AUTOSAR XML (schema 4-2-1)
standard types defined: float32, float64, sint8, sint16, sint32, uint8, uint16, uint32, boolean, dtRef_VOID, Boolean, UInt8, Float32
package /FoundationPkg/FoundationArchitecturePkg
  client server interface iCalibrate
    operation calibrateStraightAhead
      arg action: type=tCalibrateCmd, direction=IN
    operation isStraightAheadCalibrated
      arg calibrated: type=Boolean, direction=OUT
    operation getCalibrateStatus
      arg status: type=tCalibrateState, direction=OUT
  client server interface iNvmJobFinished
    operation JobFinished
      arg ServiceId: type=NvM_ServiceIdType, direction=IN
      arg JobResult: type=NvM_RequestResultType, direction=IN
  constant specification iColumnNvm_AspCalibration_Init: value-spec={short-label=iColumnNvm_AspCalibration_Init, fields=[0 deg, 1, {short-label=tStraightAheadOffset_EQf_Init, fields=[1, 1, 1, 1]}]}
  sender receiver interface iColumnNvm
    data AspCalibration: sw-calibration-access=READ-ONLY, type=tStraightAheadOffset, init-value=constant-reference=iColumnNvm_AspCalibration_Init
  client server interface iRackSizing
    operation getMaxRackTravel
      arg maxRackTravel: type=Degrees, direction=OUT
  5 x constant specification:
    iColumnData_ColumnTorque_Init: value-spec={short-label=iColumnData_ColumnTorque_Init, fields=[0 Nm, 0 Nm/s, 0, {short-label=tInputTorque_EQf_Init, fields=[1, 1, 1, 1]}]}
    iColumnData_SteeringPositionLower_Init: value-spec={short-label=iColumnData_SteeringPositionLower_Init, fields=[0 deg, 0, {short-label=tColumnPosition_EQf_Init, fields=[1, 1, 1, 1]}]}
    iColumnData_ColumnVelocity_Init: value-spec={short-label=iColumnData_ColumnVelocity_Init, fields=[0 revs/S, 0 revs/S, 0]}
    iColumnData_SteeringPositionUpper_Init: value-spec={short-label=iColumnData_SteeringPositionUpper_Init, fields=[0 deg, 0, {short-label=tColumnPosition_EQf_Init, fields=[1, 1, 1, 1]}]}
    iColumnData_ColumnPositionLower_Init: value-spec={short-label=iColumnData_ColumnPositionLower_Init, fields=[0 deg, 0, {short-label=tColumnPosition_EQf_Init, fields=[1, 1, 1, 1]}]}
  sender receiver interface iColumnData
    5 x data, all with sw-calibration-access=READ-ONLY:
      ColumnTorque: type=tInputTorque, init-value=constant-reference=iColumnData_ColumnTorque_Init
      SteeringPositionLower: type=tColumnPosition, init-value=constant-reference=iColumnData_SteeringPositionLower_Init
      ColumnVelocity: type=tColumnVelocity, init-value=constant-reference=iColumnData_ColumnVelocity_Init
      SteeringPositionUpper: type=tColumnPosition, init-value=constant-reference=iColumnData_SteeringPositionUpper_Init
      ColumnPositionLower: type=tColumnPosition, init-value=constant-reference=iColumnData_ColumnPositionLower_Init
  client server interface iResetResPositions
    operation resetResLeRiPosition
      arg StraightAheadOffSet: type=tStraightAheadOffset, direction=IN
  constant specification iStraightAheadOffset_StraightAheadOffset_Init: value-spec={short-label=iStraightAheadOffset_StraightAheadOffset_Init, fields=[0 deg, 0, {short-label=tStraightAheadOffset_EQf_Init, fields=[1, 1, 1, 1]}]}
  sender receiver interface iStraightAheadOffset
    data StraightAheadOffset: sw-calibration-access=READ-ONLY, type=tStraightAheadOffset, init-value=constant-reference=iStraightAheadOffset_StraightAheadOffset_Init
package /FoundationPkg/FoundationArchitecturePkg/FoundationTypes
  impl type tCalibrateCmd: category=VALUE, base-type=sint32, compu {0=CAL_NO_COMMAND, 1=CAL_CALIBRATE, 2=CAL_ERASE}
  compu method tCalibrateState_Compu: 0=CAL_STATE_NOT_REQUESTED, 1=CAL_STATE_IN_PROGRESS, 2=CAL_STATE_COMPLETE, 3=CAL_STATE_FAILED_ANGLE_INVALID, 4=CAL_STATE_FAILED_IMPROPER_COL_TRQ, 5=CAL_STATE_FAILED_IMPROPER_COL_VEL, 6=CAL_STATE_FAILED_NVM_WRITE
  impl type tCalibrateState: category=VALUE, base-type=sint32, compu-method=tCalibrateState_Compu
  impl type NvM_ServiceIdType: implementation-data-type=UInt8
  unit Degrees_Unit: display-name=deg
  impl type Degrees: implementation-data-type=Float32
  compu method tQualityFactor_Compu: 0=QF_UNINITIALIZED, 0=QF_UNINITIALISED, 1=QF_UNAVAILABLE, 2=QF_DEGRADED, 3=QF_FULL
  impl type tQualityFactor: category=VALUE, base-type=sint32, compu-method=tQualityFactor_Compu
  impl type tRedundancyLevel: implementation-data-type=UInt8
  impl type tExtendedQf: category=STRUCTURE
    4 x element, all with category=TYPE_REFERENCE:
      IntegrityDegraded: implementation-data-type=Boolean
      ResolutionDegraded: implementation-data-type=Boolean
      Defaulted: implementation-data-type=Boolean
      RedundancyLevel: implementation-data-type=tRedundancyLevel
  impl type tStraightAheadOffset: category=STRUCTURE
    element Value: implementation-data-type=Degrees
    element Qf: implementation-data-type=tQualityFactor
    element EQf: implementation-data-type=tExtendedQf
  unit Nm_Unit: display-name=Nm
  impl type Nm: implementation-data-type=Float32
  unit NmPerSec_Unit: display-name=Nm/s
  impl type NmPerSec: implementation-data-type=Float32
  impl type tInputTorque: category=STRUCTURE
    4 x element, all with category=TYPE_REFERENCE:
      Value: implementation-data-type=Nm
      Derivative: implementation-data-type=NmPerSec
      Qf: implementation-data-type=tQualityFactor
      EQf: implementation-data-type=tExtendedQf
  impl type tColumnPosition: category=STRUCTURE
    element Value: implementation-data-type=Degrees
    element Qf: implementation-data-type=tQualityFactor
    element EQf: implementation-data-type=tExtendedQf
  unit RevsPerSec_Unit: display-name=revs/S
  impl type RevsPerSec: implementation-data-type=Float32
  impl type tColumnVelocity: category=STRUCTURE
    element Filtered: implementation-data-type=RevsPerSec
    element Unfiltered: implementation-data-type=RevsPerSec
    element Qf: implementation-data-type=tQualityFactor
package /FoundationPkg/FoundationArchitecturePkg/FoundationTypes/ApplicationTypesPkg
  9 x app type, all with category=VALUE:
    tCalibrateCmd: base-type=sint32, compu {0=CAL_NO_COMMAND, 1=CAL_CALIBRATE, 2=CAL_ERASE}  # Calibration command - calibrate or erase.
    Boolean
    tCalibrateState: base-type=sint32, compu-method=tCalibrateState_Compu
    NvM_ServiceIdType
    UInt8
    Degrees: compu {phys=raw for raw -INF..INF; unit deg}, unit=deg
    Float32
    tQualityFactor: base-type=sint32, compu-method=tQualityFactor_Compu  # Describes the quality of an input signal.
    tRedundancyLevel: range phys 1..7  # Type used for attributes indicating a level of redundancy of some signal. i.e. could be used to indicate the number of failures required before the signal would become degraded in some way. Thus : 1 : degradation of the signal upon next failure 2 : degradation of the signal upon next 2 failures 3 : degradation of the signal upon next 3 failures and so on.
  application record data type tExtendedQf: category=STRUCTURE  # Extended quality information for a signal, used in conjunction with tQualityFactor. Legal combinations are: Qf = QF_UNINITIALISED, QF_UNINITIALIZED: eQf should be ignored. Qf = QF_UNAVAILABLE: eQf should be ignored. Qf = QF_DEGRADED: eQf - may have any combination of LossOfIntegrity, ResolutionDegraded or Defaulted set to True, and any Redundancy Level. Qf = QF_FULL: eQf Redundancy Level is the only parameter which may be used (LossOfIntegrity, ResolutionDegraded, Defaulted to be ignored).
    4 x application record element, all with category=VALUE:
      IntegrityDegraded: type=Boolean
      ResolutionDegraded: type=Boolean
      Defaulted: type=Boolean
      RedundancyLevel: type=tRedundancyLevel
  application record data type tStraightAheadOffset: category=STRUCTURE
    application record element Value: category=VALUE, type=Degrees
    application record element Qf: category=VALUE, type=tQualityFactor
    application record element EQf: category=STRUCTURE, type=tExtendedQf
  app type Nm: category=VALUE, compu {phys=raw for raw -10..10; unit Nm}, range phys -10..10, unit=Nm
  app type NmPerSec: category=VALUE, compu {phys=raw for raw -2048..2048; unit Nm/s}, range phys -2048..2048, unit=Nm/s  # Rate of change of torque
  application record data type tInputTorque: category=STRUCTURE
    4 x application record element:
      Value: category=VALUE, type=Nm
      Derivative: category=VALUE, type=NmPerSec
      Qf: category=VALUE, type=tQualityFactor
      EQf: category=STRUCTURE, type=tExtendedQf
  app type Degrees_n720_0_to_720_0: category=VALUE, compu {phys=raw for raw -720..720; unit deg}, range phys -720..720, unit=deg
  application record data type tColumnPosition: category=STRUCTURE  # Measument of the Column position in degrees with range -720 - +720.
    application record element Value: category=VALUE, type=Degrees_n720_0_to_720_0
    application record element Qf: category=VALUE, type=tQualityFactor
    application record element EQf: category=STRUCTURE, type=tExtendedQf
  app type RevsPerSec: category=VALUE, compu {phys=raw for raw -INF..INF; unit revs/S}, unit=revs/S
  application record data type tColumnVelocity: category=STRUCTURE
    application record element Filtered: category=VALUE, type=RevsPerSec
    application record element Unfiltered: category=VALUE, type=RevsPerSec
    application record element Qf: category=VALUE, type=tQualityFactor
  app type Degrees_800_to_1200: category=VALUE, compu {phys=raw for raw 800..1200; unit deg}, range phys 800..1200, unit=deg
  app type RevsPerSec_n5_to_5: category=VALUE, compu {phys=raw for raw -5..5; unit revs/S}, range phys -5..5, unit=revs/S
package /FoundationPkg/FoundationArchitecturePkg/FoundationVehicleAbstractionPkg
  constant specification CalibratableRackConfigurationSwc_CalibrateCmd_Init: value-spec=0
  constant specification CalibratableRackConfigurationSwc_CalibrateStatus_Init: value-spec=0
  constant specification CalibratableRackConfigurationSwc_NVMJobFinishedFlag_Init: value-spec=0
package /FoundationPkg/FoundationArchitecturePkg/FoundationVehicleAbstractionPkg/CalibratableRackConfigurationSwc
  constant specification PlatformTune_CALIBRATION_TRQ_THRESHOLD_Init: value-spec=0.5
  constant specification PlatformTune_CALIBRATION_VEL_THRESHOLD_Init: value-spec=0.1
package /DataTypeMappingSets
  data type mapping set MappingSet
    data-type-maps:
      application-data-type=tCalibrateCmd, implementation-data-type=tCalibrateCmd
      application-data-type=Boolean, implementation-data-type=Boolean
      application-data-type=tCalibrateState, implementation-data-type=tCalibrateState
      application-data-type=UInt8, implementation-data-type=UInt8
      application-data-type=NvM_ServiceIdType, implementation-data-type=NvM_ServiceIdType
      application-data-type=Float32, implementation-data-type=Float32
      application-data-type=Degrees, implementation-data-type=Degrees
      application-data-type=tQualityFactor, implementation-data-type=tQualityFactor
      application-data-type=tRedundancyLevel, implementation-data-type=tRedundancyLevel
      application-data-type=tExtendedQf, implementation-data-type=tExtendedQf
      application-data-type=tStraightAheadOffset, implementation-data-type=tStraightAheadOffset
      application-data-type=Nm, implementation-data-type=Nm
      application-data-type=NmPerSec, implementation-data-type=NmPerSec
      application-data-type=tInputTorque, implementation-data-type=tInputTorque
      application-data-type=Degrees_n720_0_to_720_0, implementation-data-type=Degrees
      application-data-type=tColumnPosition, implementation-data-type=tColumnPosition
      application-data-type=RevsPerSec, implementation-data-type=RevsPerSec
      application-data-type=tColumnVelocity, implementation-data-type=tColumnVelocity
      application-data-type=Degrees_800_to_1200, implementation-data-type=Degrees
      application-data-type=RevsPerSec_n5_to_5, implementation-data-type=RevsPerSec
package /SwAddrMethods
  8 x sw addr method, all with memory-allocation-keyword-policy=ADDR-METHOD-SHORT-NAME, section-type=CALIBRATION-ONLINE:
    VehicleTune
    PlatformTune
    DevelopmentTune
    SteeringTune
    SensorTune
    EppTune
    GearTune
    FeatureTune
package /GeneralMotorsPkg/GeneralMotorsArchitecturePkg/GeneralMotorsVehicleAbstractionPkg
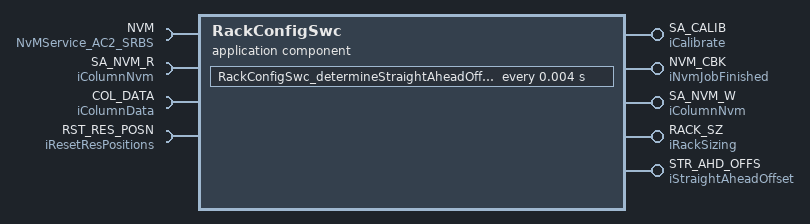
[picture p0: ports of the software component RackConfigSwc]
  application sw component type RackConfigSwc
    require port NVM: required-interface=NvMService_AC2_SRBS
    provide port SA_CALIB: provided-interface=iCalibrate  # Provide interfaces for calibration of the steering straight ahead position.
      provided-com-specs:
        operation=calibrateStraightAhead, queue-length=1
        operation=isStraightAheadCalibrated, queue-length=1
        operation=getCalibrateStatus, queue-length=1
    provide port NVM_CBK: server-com-spec{operation=JobFinished, queue-length=1}, provided-interface=iNvmJobFinished  # Callback from NVM to provide status on completion of operations.
    require port SA_NVM_R: nonqueued-receiver-com-spec{data-element=AspCalibration, init-value=constant-reference=iColumnNvm_AspCalibration_Init}, required-interface=iColumnNvm
    provide port SA_NVM_W: nonqueued-sender-com-spec{data-element=AspCalibration, init-value=constant-reference=iColumnNvm_AspCalibration_Init}, provided-interface=iColumnNvm
    provide port RACK_SZ: server-com-spec{operation=getMaxRackTravel, queue-length=1}, provided-interface=iRackSizing  # Provide configuration of the rack size
    require port COL_DATA: required-interface=iColumnData
      required-com-specs:
        data-element=ColumnTorque, init-value=constant-reference=iColumnData_ColumnTorque_Init
        data-element=SteeringPositionLower, init-value=constant-reference=iColumnData_SteeringPositionLower_Init
        data-element=ColumnVelocity, init-value=constant-reference=iColumnData_ColumnVelocity_Init
        data-element=SteeringPositionUpper, init-value=constant-reference=iColumnData_SteeringPositionUpper_Init
        data-element=ColumnPositionLower, init-value=constant-reference=iColumnData_ColumnPositionLower_Init
    require port RST_RES_POSN: required-interface=iResetResPositions
    provide port STR_AHD_OFFS: nonqueued-sender-com-spec{data-element=StraightAheadOffset, init-value=constant-reference=iStraightAheadOffset_StraightAheadOffset_Init}, provided-interface=iStraightAheadOffset
    behavior RackConfigSwc_IB: data-type-mapping=MappingSet, handle-termination-and-restart=NO-SUPPORT
      operation invoked event Event_getMaxRackTravel: start-on-event=RackConfigSwc_getMaxRackTravel, operation=RACK_SZ.getMaxRackTravel
      init event Event_Initialise_Init: start-on-event=RackConfigSwc_Initialise
      4 x operation invoked event:
        Event_JobFinished: start-on-event=RackConfigSwc_JobFinished, operation=NVM_CBK.JobFinished
        Event_calibrateStraightAhead: start-on-event=RackConfigSwc_calibrateStraightAhead, operation=SA_CALIB.calibrateStraightAhead
        Event_isStraightAheadCalibrated: start-on-event=RackConfigSwc_isStraightAheadCalibrated, operation=SA_CALIB.isStraightAheadCalibrated
        Event_getCalibrateStatus: start-on-event=RackConfigSwc_getCalibrateStatus, operation=SA_CALIB.getCalibrateStatus
      timing event Event_determineStraightAheadOffset: start-on-event=RackConfigSwc_determineStraightAheadOffset, period=0.004
      explicit-inter-runnable-variables:
        data CalibrateCmd: sw-calibration-access=READ-ONLY, type=tCalibrateCmd, init-value=constant-reference=CalibratableRackConfigurationSwc_CalibrateCmd_Init
        data CalibrateStatus: sw-calibration-access=READ-ONLY, type=tCalibrateState, init-value=constant-reference=CalibratableRackConfigurationSwc_CalibrateStatus_Init  # The current status of any calibration request. Set by calibrateStraightAhead on beginning calibration, read be getCalibrateCommandResponse and set to final value in JobFinished at completion of NVM operation.
        data NVMJobFinishedFlag: sw-calibration-access=READ-ONLY, type=tCalibrateState, init-value=constant-reference=CalibratableRackConfigurationSwc_NVMJobFinishedFlag_Init  # The current status of any calibration request. Set by calibrateStraightAhead on beginning calibration, read be getCalibrateCommandResponse and set to final value in JobFinished at completion of NVM operation.
      per-instance-parameters:
        parameter data prototype RACK_TRAVEL: category=VALUE, sw-addr-method=GearTune, sw-calibration-access=READ-WRITE, type=Degrees_800_to_1200, init-value=constant-reference=GearTune_RACK_TRAVEL_Init  # The degrees of column rotation to travel the full length of the rack.
        parameter data prototype CALIBRATION_TRQ_THRESHOLD: category=VALUE, sw-addr-method=PlatformTune, sw-calibration-access=READ-WRITE, type=Nm, init-value=constant-reference=PlatformTune_CALIBRATION_TRQ_THRESHOLD_Init  # Maximum absolute column torque value for accepting calibration request.
        parameter data prototype CALIBRATION_VEL_THRESHOLD: category=VALUE, sw-addr-method=PlatformTune, sw-calibration-access=READ-WRITE, type=RevsPerSec_n5_to_5, init-value=constant-reference=PlatformTune_CALIBRATION_VEL_THRESHOLD_Init  # Maximum absolute column velocity value for accepting calibration request.
      7 x runnable:
        RackConfigSwc_getMaxRackTravel: can-be-invoked-concurrently=true, symbol=RackConfig_getMaxRackTravel
          parameter access RACK_TRAVEL: accessed-parameter=RACK_TRAVEL
        RackConfigSwc_Initialise: symbol=RackConfig_Initialise  # Write initial value of StraightAheadOffset, using AspCalibration value from NVM.
          data-write-access:
            access W_STR_AHD_OFFS_StraightAheadOffset: accessed-variable=STR_AHD_OFFS.StraightAheadOffset
        RackConfigSwc_JobFinished: symbol=RackConfig_JobFinished
          written-local-variables:
            access WV_NVMJobFinishedFlag: accessed-variable=NVMJobFinishedFlag
        RackConfigSwc_calibrateStraightAhead: symbol=RackConfig_calibrateStraightAhead  # Request to alter the calibration of the straight ahead position. Inputs: action- perform calibration (CAL_CALIBRATE), erase calibration (CAL_ERASE) Outputs: None Note: the calibration will take place asynchronously to the request. To determine success or failure of this command the user should call getCalibrateCommandResponse()
          written-local-variables:
            access WV_CalibrateCmd: accessed-variable=CalibrateCmd
        RackConfigSwc_isStraightAheadCalibrated: symbol=RackConfig_isStraightAheadCalibrated  # Return indication of whether the straight ahead position of the steering has been calibrated. Inputs: None. Outputs: calibrated - indication of whether calibration has been performed successfully.
        RackConfigSwc_getCalibrateStatus: symbol=RackConfig_getCalibrateStatus  # Read the status of the last calibration command. Inputs: None Outputs: response: Indication of the status of the command (see enum declaration for values and meanings).
          read-local-variables:
            access RV_CalibrateStatus: accessed-variable=CalibrateStatus
        RackConfigSwc_determineStraightAheadOffset: symbol=RackConfig_determineStraightAheadOffset  # Calibrates the column straight ahead offset when triggered by the CalibrateCmd. When triggered the current column position value gets written to the NVM.
          data-read-access:
            4 x access:
              R_COL_DATA_ColumnTorque: accessed-variable=COL_DATA.ColumnTorque
              R_COL_DATA_ColumnVelocity: accessed-variable=COL_DATA.ColumnVelocity
              R_COL_DATA_ColumnPositionLower: accessed-variable=COL_DATA.ColumnPositionLower
              R_SA_NVM_R_AspCalibration: accessed-variable=SA_NVM_R.AspCalibration
          data-send-points:
            access W_SA_NVM_W_AspCalibration: accessed-variable=SA_NVM_W.AspCalibration
          data-write-access:
            access W_STR_AHD_OFFS_StraightAheadOffset: accessed-variable=STR_AHD_OFFS.StraightAheadOffset
          parameter access CALIBRATION_TRQ_THRESHOLD: accessed-parameter=CALIBRATION_TRQ_THRESHOLD
          parameter access CALIBRATION_VEL_THRESHOLD: accessed-parameter=CALIBRATION_VEL_THRESHOLD
          read-local-variables:
            access RV_CalibrateCmd: accessed-variable=CalibrateCmd
            access RV_NVMJobFinishedFlag: accessed-variable=NVMJobFinishedFlag
          sync call Call_RST_RES_POSN_resetResLeRiPosition: operation=RST_RES_POSN.resetResLeRiPosition, timeout=0
          written-local-variables:
            access WV_CalibrateStatus: accessed-variable=CalibrateStatus
      swc service dependency SwcNv_SA_NVM: assigned-ports=[{port-prototype=NVM_CBK, role=NvMNotifyJobFinished}, {port-prototype=NVM, role=NVM}]
        service-needs:
          nv block needs SwcNv_SA_NVM: calc-ram-block-crc=false, check-static-block-id=false, n-rom-blocks=1, ram-block-status-control=NV-RAM-MANAGER, readonly=false, reliability=ERROR-DETECTION, resistant-to-changed-sw=true, restore-at-start=false, store-at-shutdown=false, store-cyclic=false, store-emergency=false, store-immediate=true, use-auto-validation-at-shut-down=false, use-crc-comp-mechanism=true, write-only-once=false, write-verification=false
  constant specification GearTune_RACK_TRAVEL_Init: value-spec=1160
package /Predefined_DEV/ImplementationDataTypes
  impl type NvM_RequestResultType: compu {0=NVM_REQ_OK, 1=NVM_REQ_NOT_OK, 2=NVM_REQ_PENDING, 3=NVM_REQ_INTEGRITY_FAILED, 4=NVM_REQ_BLOCK_SKIPPED, 5=NVM_REQ_NV_INVALIDATED, 6=NVM_REQ_CANCELED, 7=NVM_REQ_REDUNDANCY_FAILED, 8=NVM_REQ_RESTORED_FROM_ROM}, implementation-data-type=uint8
package /Predefined_DEV/PortInterfaces
  client server interface NvMService_AC2_SRBS: is-service=true
    operation GetErrorStatus: possible-error=E_NOT_OK
      arg ErrorStatus: type=NvM_RequestResultType, direction=OUT, server-argument-impl-policy=USE-ARGUMENT-TYPE
    operation SetRamBlockStatus: possible-error=E_NOT_OK
      arg RamBlockStatus: type=boolean, direction=IN, server-argument-impl-policy=USE-ARGUMENT-TYPE
    error E_NOT_OK: error-code=1
